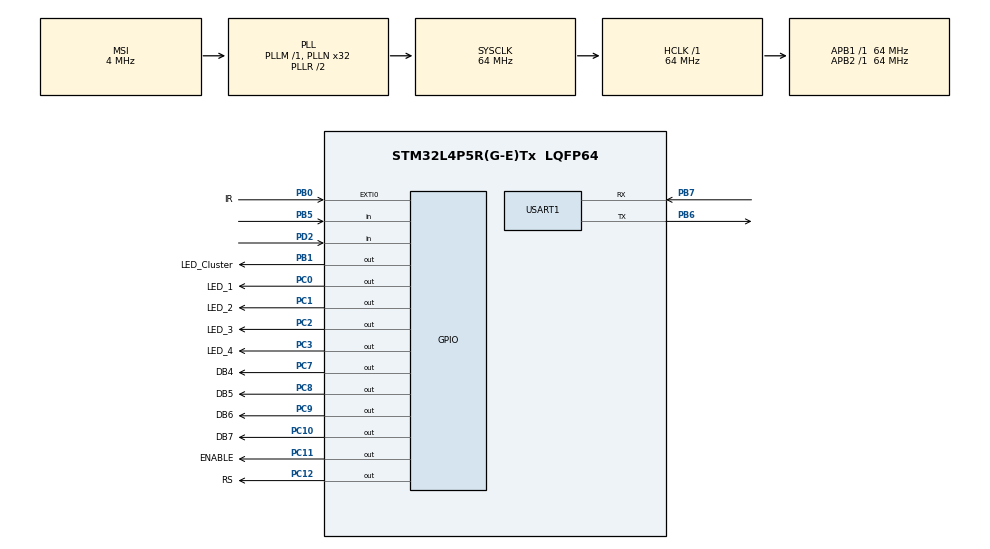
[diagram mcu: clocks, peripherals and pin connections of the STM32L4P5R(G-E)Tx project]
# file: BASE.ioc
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Mcu.Family=STM32L4
Mcu.Name=STM32L4P5R(G-E)Tx
Mcu.Package=LQFP64
NVIC.EXTI0_IRQn=true\:1\:0\:true\:false\:true\:true\:true
NVIC.PriorityGroup=NVIC_PRIORITYGROUP_4
NVIC.TIM2_IRQn=true\:0\:0\:false\:false\:true\:true\:true
PA13\ (JTMS/SWDIO).Mode=JTAG_5_pins
PA13\ (JTMS/SWDIO).Signal=SYS_JTMS-SWDIO
PA14\ (JTCK/SWCLK).Mode=JTAG_5_pins
PA14\ (JTCK/SWCLK).Signal=SYS_JTCK-SWCLK
PA15\ (JTDI).Mode=JTAG_5_pins
PA15\ (JTDI).Signal=SYS_JTDI
PB0.GPIO_Label=IR
PB0.Signal=GPXTI0
PB1.GPIO_Label=LED_Cluster
PB1.Signal=GPIO_Output
PB3\ (JTDO/TRACESWO).Mode=JTAG_5_pins
PB3\ (JTDO/TRACESWO).Signal=SYS_JTDO-SWO
PB4\ (NJTRST).Mode=JTAG_5_pins
PB4\ (NJTRST).Signal=SYS_JTRST
PB5.GPIO_Label=PB5?
PB5.Signal=GPIO_Input
PB6.Mode=Asynchronous
PB6.Signal=USART1_TX
PB7.Mode=Asynchronous
PB7.Signal=USART1_RX
PC0.GPIO_Label=LED_1
PC0.Signal=GPIO_Output
PC1.GPIO_Label=LED_2
PC1.Signal=GPIO_Output
PC10.GPIO_Label=DB7
PC10.Signal=GPIO_Output
PC11.GPIO_Label=ENABLE
PC11.Signal=GPIO_Output
PC12.GPIO_Label=RS
PC12.Signal=GPIO_Output
PC14-OSC32_IN\ (PC14).Mode=LSE-External-Oscillator
PC14-OSC32_IN\ (PC14).Signal=RCC_OSC32_IN
PC15-OSC32_OUT\ (PC15).Mode=LSE-External-Oscillator
PC15-OSC32_OUT\ (PC15).Signal=RCC_OSC32_OUT
PC2.GPIO_Label=LED_3
PC2.Signal=GPIO_Output
PC3.GPIO_Label=LED_4
PC3.Signal=GPIO_Output
PC7.GPIO_Label=DB4
PC7.Signal=GPIO_Output
PC8.GPIO_Label=DB5
PC8.Signal=GPIO_Output
PC9.GPIO_Label=DB6
PC9.Signal=GPIO_Output
PD2.GPIO_Label=PB6?
PD2.Signal=GPIO_Input
PH0-OSC_IN\ (PH0).Mode=HSE-External-Oscillator
PH0-OSC_IN\ (PH0).Signal=RCC_OSC_IN
PH1-OSC_OUT\ (PH1).Mode=HSE-External-Oscillator
PH1-OSC_OUT\ (PH1).Signal=RCC_OSC_OUT
ProjectManager.HeapSize=0x200
ProjectManager.StackSize=0x400
ProjectManager.TargetToolchain=STM32CubeIDE
RCC.ADCFreq_Value=16000000
RCC.AHBFreq_Value=64000000
RCC.APB1Freq_Value=64000000
RCC.APB1TimFreq_Value=64000000
RCC.APB2Freq_Value=64000000
RCC.APB2TimFreq_Value=64000000
RCC.CortexFreq_Value=64000000
RCC.HCLKFreq_Value=64000000
RCC.HSE_VALUE=16000000
RCC.HSI48_VALUE=48000000
RCC.HSI_VALUE=16000000
RCC.MSI_VALUE=4000000
RCC.PLLN=32
RCC.SYSCLKFreq_VALUE=64000000
RCC.SYSCLKSource=RCC_SYSCLKSOURCE_PLLCLK
RCC.USBFreq_Value=16000000
RCC.VCOOutputFreq_Value=128000000
USART1.VirtualMode-Asynchronous=VM_ASYNC
VP_TIM2_VS_ClockSourceINT.Mode=Internal
board=custom

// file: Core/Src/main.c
/* USER CODE BEGIN Header */
/**
  ******************************************************************************
  * @file           : main.c
  * @brief          : Main program body
  ******************************************************************************
  * @attention
  *
  * <h2><center>&copy; Copyright (c) 2022 STMicroelectronics.
  * All rights reserved.</center></h2>
  *
  * This software component is licensed by ST under BSD 3-Clause license,
  * the "License"; You may not use this file except in compliance with the
  * License. You may obtain a copy of the License at:
  *                        opensource.org/licenses/BSD-3-Clause
  *
  ******************************************************************************
  */
/* USER CODE END Header */
#include "main.h"
#include "LiquidCrystal.h"

TIM_HandleTypeDef htim2;

UART_HandleTypeDef huart1;

/* USER CODE BEGIN PV */
uint8_t car_passed = 1;
uint8_t show_time = 0;
uint8_t update_lcd = 0;
/* USER CODE END PV */

void SystemClock_Config(void);
static void MX_GPIO_Init(void);
static void MX_USART1_UART_Init(void);
static void MX_TIM2_Init(void);

int main(void)
{

  /* MCU Configuration--------------------------------------------------------*/

  /* Reset of all peripherals, Initializes the Flash interface and the Systick. */
  HAL_Init();

  /* Configure the system clock */
  SystemClock_Config();

  /* Initialize all configured peripherals */
  MX_GPIO_Init();
  MX_USART1_UART_Init();
  MX_TIM2_Init();
  /* USER CODE BEGIN 2 */
  LiquidCrystal(GPIOC, RS_Pin, GPIO_PIN_6, ENABLE_Pin, DB4_Pin, DB5_Pin, DB6_Pin, DB7_Pin);
  print("Starting...");
  display();
  Reset();
  /* USER CODE END 2 */

  /* Infinite loop */
  while (1)
  {

    /* USER CODE BEGIN 3 */
	  if(car_passed == 1)
	   	  {
	   		  HAL_TIM_Base_Start_IT(&htim2);
	   		  car_passed = 2;
	   	  }
	   	  else if(car_passed == 3)
	   	  {
	   		  Reset();
	   		  car_passed = 1;
	   	  }
	   	  else//Update LCD
	   	  {
	   		  if(update_lcd == 1)
	   		  {
	   			  update();
	   			  update_lcd = 0;
	   		  }
	   	  }
  }
  /* USER CODE END 3 */
}

void SystemClock_Config(void)
{
  RCC_OscInitTypeDef RCC_OscInitStruct = {0};
  RCC_ClkInitTypeDef RCC_ClkInitStruct = {0};

  /** Configure the main internal regulator output voltage
  */
  if (HAL_PWREx_ControlVoltageScaling(PWR_REGULATOR_VOLTAGE_SCALE1) != HAL_OK)
  {
    Error_Handler();
  }
  /** Initializes the RCC Oscillators according to the specified parameters
  * in the RCC_OscInitTypeDef structure.
  */
  RCC_OscInitStruct.OscillatorType = RCC_OSCILLATORTYPE_MSI;
  RCC_OscInitStruct.MSIState = RCC_MSI_ON;
  RCC_OscInitStruct.MSICalibrationValue = 0;
  RCC_OscInitStruct.MSIClockRange = RCC_MSIRANGE_6;
  RCC_OscInitStruct.PLL.PLLState = RCC_PLL_ON;
  RCC_OscInitStruct.PLL.PLLSource = RCC_PLLSOURCE_MSI;
  RCC_OscInitStruct.PLL.PLLM = 1;
  RCC_OscInitStruct.PLL.PLLN = 32;
  RCC_OscInitStruct.PLL.PLLP = RCC_PLLP_DIV2;
  RCC_OscInitStruct.PLL.PLLQ = RCC_PLLQ_DIV2;
  RCC_OscInitStruct.PLL.PLLR = RCC_PLLR_DIV2;
  if (HAL_RCC_OscConfig(&RCC_OscInitStruct) != HAL_OK)
  {
    Error_Handler();
  }
  /** Initializes the CPU, AHB and APB buses clocks
  */
  RCC_ClkInitStruct.ClockType = RCC_CLOCKTYPE_HCLK|RCC_CLOCKTYPE_SYSCLK
                              |RCC_CLOCKTYPE_PCLK1|RCC_CLOCKTYPE_PCLK2;
  RCC_ClkInitStruct.SYSCLKSource = RCC_SYSCLKSOURCE_PLLCLK;
  RCC_ClkInitStruct.AHBCLKDivider = RCC_SYSCLK_DIV1;
  RCC_ClkInitStruct.APB1CLKDivider = RCC_HCLK_DIV1;
  RCC_ClkInitStruct.APB2CLKDivider = RCC_HCLK_DIV1;

  if (HAL_RCC_ClockConfig(&RCC_ClkInitStruct, FLASH_LATENCY_3) != HAL_OK)
  {
    Error_Handler();
  }
}

static void MX_TIM2_Init(void)
{

  TIM_ClockConfigTypeDef sClockSourceConfig = {0};
  TIM_MasterConfigTypeDef sMasterConfig = {0};

  htim2.Instance = TIM2;
  htim2.Init.Prescaler = 0;
  htim2.Init.CounterMode = TIM_COUNTERMODE_UP;
  htim2.Init.Period = 4294967295;
  htim2.Init.ClockDivision = TIM_CLOCKDIVISION_DIV1;
  htim2.Init.AutoReloadPreload = TIM_AUTORELOAD_PRELOAD_DISABLE;
  if (HAL_TIM_Base_Init(&htim2) != HAL_OK)
  {
    Error_Handler();
  }
  sClockSourceConfig.ClockSource = TIM_CLOCKSOURCE_INTERNAL;
  if (HAL_TIM_ConfigClockSource(&htim2, &sClockSourceConfig) != HAL_OK)
  {
    Error_Handler();
  }
  sMasterConfig.MasterOutputTrigger = TIM_TRGO_RESET;
  sMasterConfig.MasterSlaveMode = TIM_MASTERSLAVEMODE_DISABLE;
  if (HAL_TIMEx_MasterConfigSynchronization(&htim2, &sMasterConfig) != HAL_OK)
  {
    Error_Handler();
  }

}

static void MX_USART1_UART_Init(void)
{

  huart1.Instance = USART1;
  huart1.Init.BaudRate = 115200;
  huart1.Init.WordLength = UART_WORDLENGTH_8B;
  huart1.Init.StopBits = UART_STOPBITS_1;
  huart1.Init.Parity = UART_PARITY_NONE;
  huart1.Init.Mode = UART_MODE_TX_RX;
  huart1.Init.HwFlowCtl = UART_HWCONTROL_NONE;
  huart1.Init.OverSampling = UART_OVERSAMPLING_16;
  huart1.Init.OneBitSampling = UART_ONE_BIT_SAMPLE_DISABLE;
  huart1.Init.ClockPrescaler = UART_PRESCALER_DIV1;
  huart1.AdvancedInit.AdvFeatureInit = UART_ADVFEATURE_NO_INIT;
  if (HAL_UART_Init(&huart1) != HAL_OK)
  {
    Error_Handler();
  }
  if (HAL_UARTEx_SetTxFifoThreshold(&huart1, UART_TXFIFO_THRESHOLD_1_8) != HAL_OK)
  {
    Error_Handler();
  }
  if (HAL_UARTEx_SetRxFifoThreshold(&huart1, UART_RXFIFO_THRESHOLD_1_8) != HAL_OK)
  {
    Error_Handler();
  }
  if (HAL_UARTEx_DisableFifoMode(&huart1) != HAL_OK)
  {
    Error_Handler();
  }

}

static void MX_GPIO_Init(void)
{
  GPIO_InitTypeDef GPIO_InitStruct = {0};

  /* GPIO Ports Clock Enable */
  __HAL_RCC_GPIOC_CLK_ENABLE();
  __HAL_RCC_GPIOH_CLK_ENABLE();
  __HAL_RCC_GPIOB_CLK_ENABLE();
  __HAL_RCC_GPIOA_CLK_ENABLE();
  __HAL_RCC_GPIOD_CLK_ENABLE();

  /*Configure GPIO pin Output Level */
  HAL_GPIO_WritePin(GPIOC, LED_1_Pin|LED_2_Pin|LED_3_Pin|LED_4_Pin
                          |DB4_Pin|DB5_Pin|DB6_Pin|DB7_Pin
                          |ENABLE_Pin|RS_Pin, GPIO_PIN_RESET);

  /*Configure GPIO pin Output Level */
  HAL_GPIO_WritePin(LED_s_IR_GPIO_Port, LED_s_IR_Pin, GPIO_PIN_RESET);

  /*Configure GPIO pins : LED_1_Pin LED_2_Pin LED_3_Pin LED_4_Pin
                           DB4_Pin DB5_Pin DB6_Pin DB7_Pin
                           ENABLE_Pin RS_Pin */
  GPIO_InitStruct.Pin = LED_1_Pin|LED_2_Pin|LED_3_Pin|LED_4_Pin
                          |DB4_Pin|DB5_Pin|DB6_Pin|DB7_Pin
                          |ENABLE_Pin|RS_Pin;
  GPIO_InitStruct.Mode = GPIO_MODE_OUTPUT_PP;
  GPIO_InitStruct.Pull = GPIO_NOPULL;
  GPIO_InitStruct.Speed = GPIO_SPEED_FREQ_LOW;
  HAL_GPIO_Init(GPIOC, &GPIO_InitStruct);

  /*Configure GPIO pin : IR_Pin */
  GPIO_InitStruct.Pin = IR_Pin;
  GPIO_InitStruct.Mode = GPIO_MODE_IT_RISING;
  GPIO_InitStruct.Pull = GPIO_NOPULL;
  HAL_GPIO_Init(IR_GPIO_Port, &GPIO_InitStruct);

  /*Configure GPIO pin : LED_s_IR_Pin */
  GPIO_InitStruct.Pin = LED_s_IR_Pin;
  GPIO_InitStruct.Mode = GPIO_MODE_OUTPUT_PP;
  GPIO_InitStruct.Pull = GPIO_NOPULL;
  GPIO_InitStruct.Speed = GPIO_SPEED_FREQ_LOW;
  HAL_GPIO_Init(LED_s_IR_GPIO_Port, &GPIO_InitStruct);

  /*Configure GPIO pin : PB6__Pin */
  GPIO_InitStruct.Pin = PB6__Pin;
  GPIO_InitStruct.Mode = GPIO_MODE_INPUT;
  GPIO_InitStruct.Pull = GPIO_NOPULL;
  HAL_GPIO_Init(PB6__GPIO_Port, &GPIO_InitStruct);

  /*Configure GPIO pin : PB5__Pin */
  GPIO_InitStruct.Pin = PB5__Pin;
  GPIO_InitStruct.Mode = GPIO_MODE_INPUT;
  GPIO_InitStruct.Pull = GPIO_NOPULL;
  HAL_GPIO_Init(PB5__GPIO_Port, &GPIO_InitStruct);

  /* EXTI interrupt init*/
  HAL_NVIC_SetPriority(EXTI0_IRQn, 1, 0);
  HAL_NVIC_EnableIRQ(EXTI0_IRQn);

}

void Error_Handler(void)
{
  __disable_irq();
  while (1)
  {
  }
}

/************************ (C) COPYRIGHT STMicroelectronics *****END OF FILE****/
